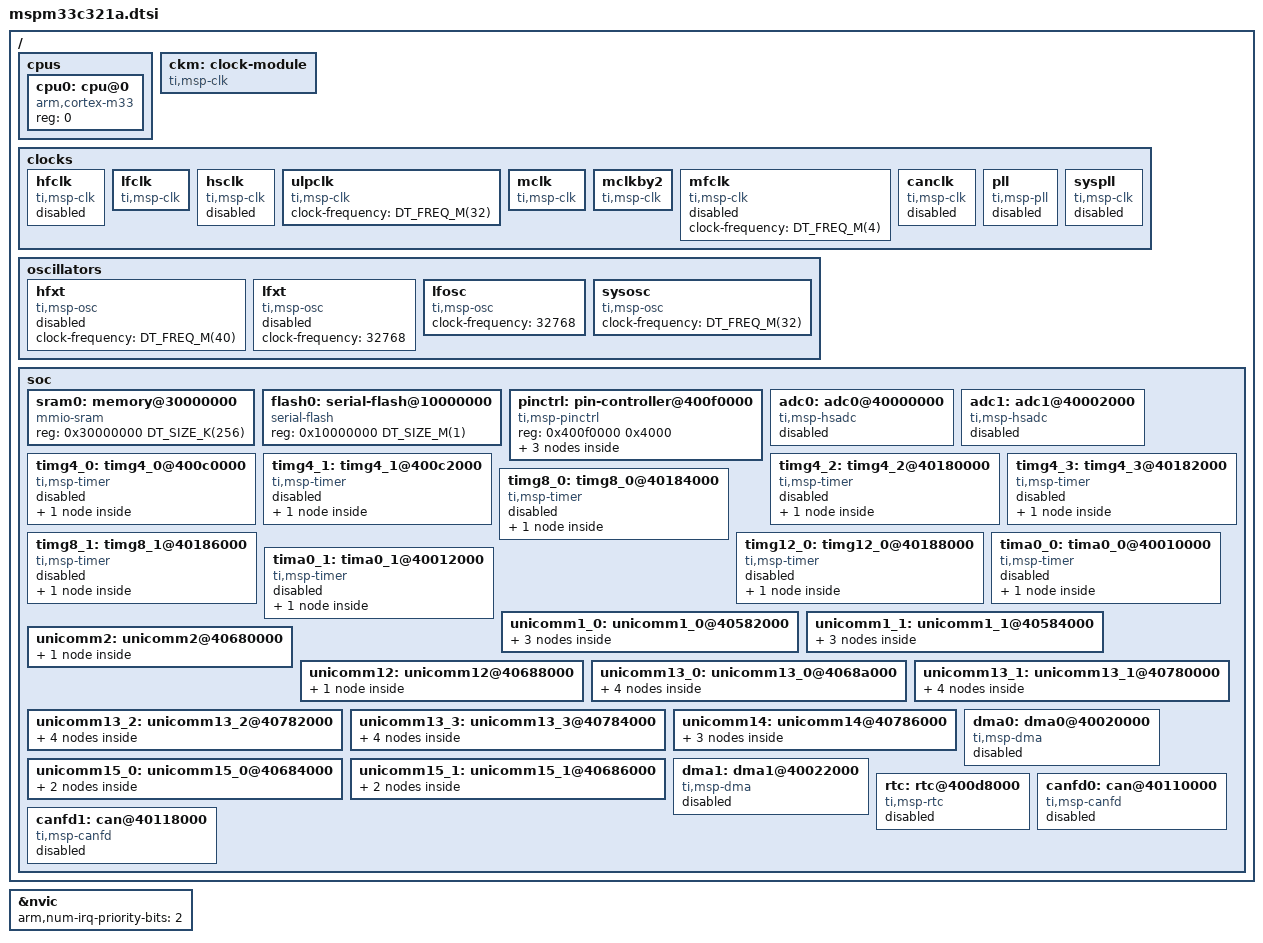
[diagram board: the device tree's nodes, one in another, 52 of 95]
/*
 * Copyright (c) 2025 Texas Instruments
 *
 * SPDX-License-Identifier: Apache-2.0
 */

#include <arm/armv8-m.dtsi>
#include <mem.h>
#include <freq.h>
#include <zephyr/dt-bindings/clock/msp_clock.h>

/{
	cpus {
		#address-cells = <1>;
		#size-cells = <0>;

		cpu0: cpu@0 {
			device_type = "cpu";
			compatible = "arm,cortex-m33";
			reg = <0>;
			#address-cells = <1>;
			#size-cells = <1>;
		};
	};

	ckm: clock-module {
		compatible = "ti,msp-clk";
		#clock-cells = <1>;
	};

	clocks: clocks {
		hfclk: hfclk {
			#clock-cells = <1>;
			compatible = "ti,msp-clk";
			status = "disabled";
		};

		lfclk: lfclk {
			#clock-cells = <1>;
			compatible = "ti,msp-clk";
			clock-frequency = <32768>;
			clocks = <&lfosc>;
		};

		hsclk: hsclk {
			#clock-cells = <1>;
			compatible = "ti,msp-clk";
			status = "disabled";
		};

		ulpclk: ulpclk {
			#clock-cells = <1>;
			compatible = "ti,msp-clk";
			clock-frequency = <DT_FREQ_M(32)>;
		};

		mclk: mclk {
			#clock-cells = <1>;
			compatible = "ti,msp-clk";
			clock-frequency = <DT_FREQ_M(32)>;
			clocks = <&sysosc>;
		};

		mclkby2: mclkby2 {
			#clock-cells = <1>;
			compatible = "ti,msp-clk";
		};

		mfclk: mfclk {
			#clock-cells = <1>;
			compatible = "ti,msp-clk";
			clock-frequency = <DT_FREQ_M(4)>;
			status = "disabled";
		};

		canclk: canclk {
			#clock-cells = <1>;
			compatible = "ti,msp-clk";
			status = "disabled";
		};

		pll: pll {
			compatible = "ti,msp-pll";
			clocks = <&sysosc>;
			p-div = <1>;
			q-div = <10>;
			clk1-div = <1>;
			clk0-div = <1>;
			clk2x-div = <1>;
			#clock-cells = <0>;
			status = "disabled";
		};

		syspll: syspll {
			#clock-cells = <1>;
			compatible = "ti,msp-clk";
			status = "disabled";
		};
	};

	oscillators: oscillators {
		hfxt: hfxt {
			#clock-cells = <0>;
			compatible = "ti,msp-osc";
			clock-frequency = <DT_FREQ_M(40)>;
			status = "disabled";
		};

		lfxt: lfxt {
			#clock-cells = <0>;
			compatible = "ti,msp-osc";
			clock-frequency = <32768>;
			status = "disabled";
		};

		lfosc: lfosc {
			#clock-cells = <0>;
			compatible = "ti,msp-osc";
			clock-frequency = <32768>;
		};

		sysosc: sysosc {
			#clock-cells = <0>;
			compatible = "ti,msp-osc";
			clock-frequency = <DT_FREQ_M(32)>;
		};
	};

	soc {

		sram0: memory@30000000 {
			compatible = "mmio-sram";
			reg = <0x30000000 DT_SIZE_K(256)>;
		};

		flash0: serial-flash@10000000 {
			compatible = "serial-flash";
			reg = <0x10000000 DT_SIZE_M(1)>;
		};

		pinctrl: pin-controller@400f0000 {
			compatible = "ti,msp-pinctrl";
			#address-cells = <1>;
			#size-cells = <1>;
			reg = <0x400f0000 0x4000>;

			gpioa: gpio@400f0000 {
				compatible = "ti,msp-gpio";
				reg = <0x400f0000 0x2000>;
				interrupts = <6 0>;
				status = "disabled";
				gpio-controller;
				#gpio-cells = <2>;
			};

			gpiob: gpio@400f2000 {
				compatible = "ti,msp-gpio";
				reg = <0x400f2000 0x2000>;
				interrupts = <7 0>;
				status = "disabled";
				gpio-controller;
				#gpio-cells = <2>;
			};

			gpioc: gpio@400f4000 {
				compatible = "ti,msp-gpio";
				reg = <0x400f4000 0x2000>;
				interrupts = <8 0>;
				status = "disabled";
				gpio-controller;
				#gpio-cells = <2>;
			};
		};

		adc0: adc0@40000000 {
			compatible = "ti,msp-hsadc";
			reg = <0x40000000 0x2000>,  /* adc0 (ADC_LITE_REGS) */
			      <0x40004000 0x2000>;  /* adc0 (ADC_LITE_RESULT_REGS) */
			reg-names = "config", "result";
			interrupts = <9 0>;
			ti,clk-divider = <2>;
			dmas = <&dma0 0 5>;
			status = "disabled";
			#io-channel-cells = <1>;
		};

		adc1: adc1@40002000 {
			compatible = "ti,msp-hsadc";
			reg = <0x40002000 0x2000>,  /* adc1 (ADC_LITE_REGS) */
			      <0x40006000 0x2000>;  /* adc1 (ADC_LITE_RESULT_REGS) */
			reg-names = "config", "result";
			interrupts = <14 0>;
			ti,clk-divider = <2>;
			dmas = <&dma0 1 9>;
			status = "disabled";
			#io-channel-cells = <1>;
		};


		timg4_0: timg4_0@400c0000 {
			compatible = "ti,msp-timer";
			reg = <0x400c0000 0x2000>;
			clocks = <&ckm MSP_CLOCK_LFCLK>;
			interrupts = <21 0>;
			ti,clk-prescaler = <255>;
			ti,clk-div = <1>;
			status = "disabled";


			counterg4_0: counterg4_0 {
				compatible = "ti,msp-timer-counter";
				resolution = <16>;
				status = "disabled";
			};
		};

		timg4_1: timg4_1@400c2000 {
			compatible = "ti,msp-timer";
			reg = <0x400c2000 0x2000>;
			clocks = <&ckm MSP_CLOCK_LFCLK>;
			interrupts = <22 0>;
			ti,clk-prescaler = <255>;
			ti,clk-div = <1>;
			status = "disabled";


			counterg4_1: counterg4_1 {
				compatible = "ti,msp-timer-counter";
				resolution = <16>;
				status = "disabled";
			};
		};

		timg4_2: timg4_2@40180000 {
			compatible = "ti,msp-timer";
			reg = <0x40180000 0x2000>;
			clocks = <&ckm MSP_CLOCK_MCLKBY2>;
			interrupts = <35 0>;
			ti,clk-prescaler = <255>;
			ti,clk-div = <1>;
			status = "disabled";


			counterg4_2: counterg4_2 {
				compatible = "ti,msp-timer-counter";
				resolution = <16>;
				status = "disabled";
			};
		};

		timg4_3: timg4_3@40182000 {
			compatible = "ti,msp-timer";
			reg = <0x40182000 0x2000>;
			clocks = <&ckm MSP_CLOCK_MCLKBY2>;
			interrupts = <36 0>;
			ti,clk-prescaler = <255>;
			ti,clk-div = <1>;
			status = "disabled";


			counterg4_3: counterg4_3 {
				compatible = "ti,msp-timer-counter";
				resolution = <16>;
				status = "disabled";
			};
		};

		timg8_0: timg8_0@40184000 {
			compatible = "ti,msp-timer";
			reg = <0x40184000 0x2000>;
			clocks = <&ckm MSP_CLOCK_MCLKBY2>;
			interrupts = <23 0>;
			ti,clk-prescaler = <255>;
			ti,clk-div = <1>;
			status = "disabled";


			counterg8_0: counterg8_0 {
				compatible = "ti,msp-timer-counter";
				resolution = <16>;
				status = "disabled";
			};
		};

		timg8_1: timg8_1@40186000 {
			compatible = "ti,msp-timer";
			reg = <0x40186000 0x2000>;
			clocks = <&ckm MSP_CLOCK_MCLKBY2>;
			interrupts = <37 0>;
			ti,clk-prescaler = <255>;
			ti,clk-div = <1>;
			status = "disabled";


			counterg8_1: counterg8_1 {
				compatible = "ti,msp-timer-counter";
				resolution = <16>;
				status = "disabled";
			};
		};

		timg12_0: timg12_0@40188000 {
			compatible = "ti,msp-timer";
			reg = <0x40188000 0x2000>;
			clocks = <&ckm MSP_CLOCK_MCLKBY2>;
			interrupts = <24 0>;
			ti,clk-div = <1>;
			status = "disabled";


			counterg12_0: counterg12_0 {
				compatible = "ti,msp-timer-counter";
				resolution = <32>;
				status = "disabled";
			};
		};

		tima0_0: tima0_0@40010000 {
			compatible = "ti,msp-timer";
			reg = <0x40010000 0x2000>;
			clocks = <&ckm MSP_CLOCK_MCLK>;
			interrupts = <20 0>;
			ti,clk-prescaler = <255>;
			ti,clk-div = <1>;
			status = "disabled";


			countera0_0: countera0_0 {
				compatible = "ti,msp-timer-counter";
				resolution = <16>;
				status = "disabled";
			};
		};

		tima0_1: tima0_1@40012000 {
			compatible = "ti,msp-timer";
			reg = <0x40012000 0x2000>;
			clocks = <&ckm MSP_CLOCK_MCLK>;
			interrupts = <34 0>;
			ti,clk-prescaler = <255>;
			ti,clk-div = <1>;
			status = "disabled";


			countera0_1: countera0_1 {
				compatible = "ti,msp-timer-counter";
				resolution = <16>;
				status = "disabled";
			};
		};

		unicomm1_0: unicomm1_0@40582000 {
			reg = <0x40582000 0x00002000>;
			interrupts = <25 0>;
			#address-cells = <1>;
			#size-cells = <1>;

			unicomm1_0_uart: unicomm1_0_uart@40582000 {
				compatible = "ti,msp-uart";
				interrupts = <25 0>;
				reg = <0x40582000 0x00002000>;
				clocks = <&ckm MSP_CLOCK_ULPCLK>;
				status = "disabled";
			};

			unicomm1_0_i2cc: unicomm1_0_i2cc@40582000 {
				compatible = "ti,msp-i2c";
				interrupts = <25 0>;
				reg = <0x40582000 0x00002000>;
				clocks = <&ckm MSP_CLOCK_ULPCLK>;
				status = "disabled";
			};

			unicomm1_0_i2ct: unicomm1_0_i2ct@40582000 {
				compatible = "ti,msp-i2c";
				interrupts = <25 0>;
				reg = <0x40582000 0x00002000>;
				clocks = <&ckm MSP_CLOCK_ULPCLK>;
				status = "disabled";
			};
		};

		unicomm1_1: unicomm1_1@40584000 {
			reg = <0x40584000 0x00002000>;
			interrupts = <26 0>;
			#address-cells = <1>;
			#size-cells = <1>;

			unicomm1_1_uart: unicomm1_1_uart@40584000 {
				compatible = "ti,msp-uart";
				interrupts = <26 0>;
				reg = <0x40584000 0x00002000>;
				clocks = <&ckm MSP_CLOCK_ULPCLK>;
				status = "disabled";
			};

			unicomm1_1_i2cc: unicomm1_1_i2cc@40584000 {
				compatible = "ti,msp-i2c";
				interrupts = <26 0>;
				reg = <0x40584000 0x00002000>;
				clocks = <&ckm MSP_CLOCK_ULPCLK>;
				status = "disabled";
			};

			unicomm1_1_i2ct: unicomm1_1_i2ct@40584000 {
				compatible = "ti,msp-i2c";
				interrupts = <26 0>;
				reg = <0x40584000 0x00002000>;
				clocks = <&ckm MSP_CLOCK_ULPCLK>;
				status = "disabled";
			};
		};

		unicomm2: unicomm2@40680000 {
			reg = <0x40680000 0x00002000>;
			interrupts = <27 0>;
			#address-cells = <1>;
			#size-cells = <1>;

			unicomm2_spi: unicomm2_spi@40680000 {
				compatible = "ti,msp-spi";
				interrupts = <27 0>;
				reg = <0x40680000 0x00002000>;
				#address-cells = <1>;
				#size-cells = <0>;
				clocks = <&ckm MSP_CLOCK_MCLKBY2>;
				status = "disabled";
			};
		};

		unicomm12: unicomm12@40688000 {
			reg = <0x40688000 0x00002000>;
			interrupts = <30 0>;
			#address-cells = <1>;
			#size-cells = <1>;

			unicomm12_uart: unicomm12_uart@40688000 {
				compatible = "ti,msp-uart";
				interrupts = <30 0>;
				reg = <0x40688000 0x00002000>;
				clocks = <&ckm MSP_CLOCK_MCLKBY2>;
				status = "disabled";
			};
		};

		unicomm13_0: unicomm13_0@4068a000 {
			reg = <0x4068a000 0x00002000>;
			interrupts = <31 0>;
			#address-cells = <1>;
			#size-cells = <1>;

			unicomm13_0_uart: unicomm13_0_uart@4068a000 {
				compatible = "ti,msp-uart";
				interrupts = <31 0>;
				reg = <0x4068a000 0x00002000>;
				clocks = <&ckm MSP_CLOCK_MCLKBY2>;
				status = "disabled";
			};

			unicomm13_0_spi: unicomm13_0_spi@4068a000 {
				compatible = "ti,msp-spi";
				interrupts = <31 0>;
				reg = <0x4068a000 0x00002000>;
				#address-cells = <1>;
				#size-cells = <0>;
				clocks = <&ckm MSP_CLOCK_MCLKBY2>;
				status = "disabled";
			};

			unicomm13_0_i2cc: unicomm13_0_i2cc@4068a000 {
				compatible = "ti,msp-i2c";
				interrupts = <31 0>;
				reg = <0x4068a000 0x00002000>;
				clocks = <&ckm MSP_CLOCK_MCLKBY2>;
				status = "disabled";
			};

			unicomm13_0_i2ct: unicomm13_0_i2ct@4068a000 {
				compatible = "ti,msp-i2c";
				interrupts = <31 0>;
				reg = <0x4068a000 0x00002000>;
				clocks = <&ckm MSP_CLOCK_MCLKBY2>;
				status = "disabled";
			};
		};

		unicomm13_1: unicomm13_1@40780000 {
			reg = <0x40780000 0x00002000>;
			interrupts = <50 0>;
			#address-cells = <1>;
			#size-cells = <1>;

			unicomm13_1_uart: unicomm13_1_uart@40780000 {
				compatible = "ti,msp-uart";
				interrupts = <50 0>;
				reg = <0x40780000 0x00002000>;
				clocks = <&ckm MSP_CLOCK_MCLKBY2>;
				status = "disabled";
			};

			unicomm13_1_spi: unicomm13_1_spi@40780000 {
				compatible = "ti,msp-spi";
				interrupts = <50 0>;
				reg = <0x40780000 0x00002000>;
				#address-cells = <1>;
				#size-cells = <0>;
				clocks = <&ckm MSP_CLOCK_MCLKBY2>;
				status = "disabled";
			};

			unicomm13_1_i2cc: unicomm13_1_i2cc@40780000 {
				compatible = "ti,msp-i2c";
				interrupts = <50 0>;
				reg = <0x40780000 0x00002000>;
				clocks = <&ckm MSP_CLOCK_MCLKBY2>;
				status = "disabled";
			};

			unicomm13_1_i2ct: unicomm13_1_i2ct@40780000 {
				compatible = "ti,msp-i2c";
				interrupts = <50 0>;
				reg = <0x40780000 0x00002000>;
				clocks = <&ckm MSP_CLOCK_MCLKBY2>;
				status = "disabled";
			};
		};

		unicomm13_2: unicomm13_2@40782000 {
			reg = <0x40782000 0x00002000>;
			interrupts = <51 0>;
			#address-cells = <1>;
			#size-cells = <1>;

			unicomm13_2_uart: unicomm13_2_uart@40782000 {
				compatible = "ti,msp-uart";
				interrupts = <51 0>;
				reg = <0x40782000 0x00002000>;
				clocks = <&ckm MSP_CLOCK_MCLKBY2>;
				status = "disabled";
			};

			unicomm13_2_spi: unicomm13_2_spi@40782000 {
				compatible = "ti,msp-spi";
				interrupts = <51 0>;
				reg = <0x40782000 0x00002000>;
				#address-cells = <1>;
				#size-cells = <0>;
				clocks = <&ckm MSP_CLOCK_MCLKBY2>;
				status = "disabled";
			};

			unicomm13_2_i2cc: unicomm13_2_i2cc@40782000 {
				compatible = "ti,msp-i2c";
				interrupts = <51 0>;
				reg = <0x40782000 0x00002000>;
				clocks = <&ckm MSP_CLOCK_MCLKBY2>;
				status = "disabled";
			};

			unicomm13_2_i2ct: unicomm13_2_i2ct@40782000 {
				compatible = "ti,msp-i2c";
				interrupts = <51 0>;
				reg = <0x40782000 0x00002000>;
				clocks = <&ckm MSP_CLOCK_MCLKBY2>;
				status = "disabled";
			};
		};

		unicomm13_3: unicomm13_3@40784000 {
			reg = <0x40784000 0x00002000>;
			interrupts = <52 0>;
			#address-cells = <1>;
			#size-cells = <1>;

			unicomm13_3_uart: unicomm13_3_uart@40784000 {
				compatible = "ti,msp-uart";
				interrupts = <52 0>;
				reg = <0x40784000 0x00002000>;
				clocks = <&ckm MSP_CLOCK_MCLKBY2>;
				status = "disabled";
			};

			unicomm13_3_spi: unicomm13_3_spi@40784000 {
				compatible = "ti,msp-spi";
				interrupts = <52 0>;
				reg = <0x40784000 0x00002000>;
				#address-cells = <1>;
				#size-cells = <0>;
				clocks = <&ckm MSP_CLOCK_MCLKBY2>;
				status = "disabled";
			};

			unicomm13_3_i2cc: unicomm13_3_i2cc@40784000 {
				compatible = "ti,msp-i2c";
				interrupts = <52 0>;
				reg = <0x40784000 0x00002000>;
				clocks = <&ckm MSP_CLOCK_MCLKBY2>;
				status = "disabled";
			};

			unicomm13_3_i2ct: unicomm13_3_i2ct@40784000 {
				compatible = "ti,msp-i2c";
				interrupts = <52 0>;
				reg = <0x40784000 0x00002000>;
				clocks = <&ckm MSP_CLOCK_MCLKBY2>;
				status = "disabled";
			};
		};

		unicomm14: unicomm14@40786000 {
			reg = <0x40786000 0x00002000>;
			interrupts = <32 0>;
			#address-cells = <1>;
			#size-cells = <1>;

			unicomm14_uart: unicomm14_uart@40786000 {
				compatible = "ti,msp-uart";
				interrupts = <32 0>;
				reg = <0x40786000 0x00002000>;
				clocks = <&ckm MSP_CLOCK_MCLKBY2>;
				status = "disabled";
			};

			unicomm14_i2cc: unicomm14_i2cc@40786000 {
				compatible = "ti,msp-i2c";
				interrupts = <32 0>;
				reg = <0x40786000 0x00002000>;
				clocks = <&ckm MSP_CLOCK_MCLKBY2>;
				status = "disabled";
			};

			unicomm14_i2ct: unicomm14_i2ct@40786000 {
				compatible = "ti,msp-i2c";
				interrupts = <32 0>;
				reg = <0x40786000 0x00002000>;
				clocks = <&ckm MSP_CLOCK_MCLKBY2>;
				status = "disabled";
			};
		};

		unicomm15_0: unicomm15_0@40684000 {
			reg = <0x40684000 0x00002000>;
			interrupts = <28 0>;
			#address-cells = <1>;
			#size-cells = <1>;

			unicomm15_0_i2cc: unicomm15_0_i2cc@40684000 {
				compatible = "ti,msp-i2c";
				interrupts = <28 0>;
				reg = <0x40684000 0x00002000>;
				clocks = <&ckm MSP_CLOCK_MCLKBY2>;
				status = "disabled";
			};

			unicomm15_0_i2ct: unicomm15_0_i2ct@40684000 {
				compatible = "ti,msp-i2c";
				interrupts = <28 0>;
				reg = <0x40684000 0x00002000>;
				clocks = <&ckm MSP_CLOCK_MCLKBY2>;
				status = "disabled";
			};
		};

		unicomm15_1: unicomm15_1@40686000 {
			reg = <0x40686000 0x00002000>;
			interrupts = <29 0>;
			#address-cells = <1>;
			#size-cells = <1>;

			unicomm15_1_i2cc: unicomm15_1_i2cc@40686000 {
				compatible = "ti,msp-i2c";
				interrupts = <29 0>;
				reg = <0x40686000 0x00002000>;
				clocks = <&ckm MSP_CLOCK_MCLKBY2>;
				status = "disabled";
			};

			unicomm15_1_i2ct: unicomm15_1_i2ct@40686000 {
				compatible = "ti,msp-i2c";
				interrupts = <29 0>;
				reg = <0x40686000 0x00002000>;
				clocks = <&ckm MSP_CLOCK_MCLKBY2>;
				status = "disabled";
			};
		};

		dma0: dma0@40020000 {
			compatible = "ti,msp-dma";
			reg = <0x40020000 0x2000>;
			interrupts = <43 0>;
			#dma-cells = <2>;
			dma-channels = <4>;
			status = "disabled";
		};

		dma1: dma1@40022000 {
			compatible = "ti,msp-dma";
			reg = <0x40022000 0x2000>;
			interrupts = <44 0>;
			#dma-cells = <2>;
			dma-channels = <12>;
			status = "disabled";
		};

		rtc: rtc@400d8000 {
			compatible = "ti,msp-rtc";
			reg = <0x400d8000 0x2000>;
			interrupts = <42 0>;
			alarms-count = <2>;
			ti,rtc-x;
			status = "disabled";
		};

		canfd0: can@40110000 {
			compatible = "ti,msp-canfd";
			reg = <0x40110000 0x8000>, <0x40117000 0x1000>, <0x40110000 0x400>;
			reg-names = "ti_canfd", "m_can", "message_ram";
			interrupts = <19 0>;
			clocks = <&ckm MSP_CLOCK_CANCLK>;
			bosch,mram-cfg = <0x0 20 8 3 3 0 3 3>;
			status = "disabled";
		};

		canfd1: can@40118000 {
			compatible = "ti,msp-canfd";
			reg = <0x40118000 0x8000>, <0x4011f000 0x1000>, <0x40118000 0x400>;
			reg-names = "ti_canfd", "m_can", "message_ram";
			interrupts = <33 0>;
			clocks = <&ckm MSP_CLOCK_CANCLK>;
			bosch,mram-cfg = <0x0 20 8 3 3 0 3 3>;
			status = "disabled";
		};
	};
};

&nvic {
	arm,num-irq-priority-bits = <2>;
};
